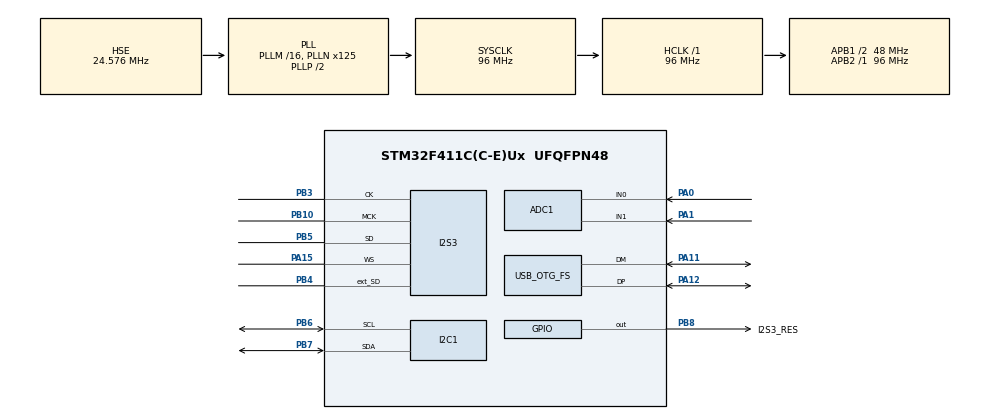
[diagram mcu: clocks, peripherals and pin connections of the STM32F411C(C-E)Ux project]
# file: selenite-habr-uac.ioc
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ADC1.Channel-0\#ChannelRegularConversion=ADC_CHANNEL_0
ADC1.Channel-1\#ChannelRegularConversion=ADC_CHANNEL_1
ADC1.ContinuousConvMode=DISABLE
ADC1.DMAContinuousRequests=ENABLE
ADC1.DataAlign=ADC_DATAALIGN_RIGHT
ADC1.ExternalTrigConv=ADC_EXTERNALTRIGCONV_T2_TRGO
ADC1.ExternalTrigConvEdge=ADC_EXTERNALTRIGCONVEDGE_RISINGFALLING
ADC1.NbrOfConversion=2
ADC1.NbrOfConversionFlag=1
ADC1.Rank-0\#ChannelRegularConversion=1
ADC1.Rank-1\#ChannelRegularConversion=2
ADC1.SamplingTime-0\#ChannelRegularConversion=ADC_SAMPLETIME_15CYCLES
ADC1.SamplingTime-1\#ChannelRegularConversion=ADC_SAMPLETIME_15CYCLES
ADC1.master=1
Dma.ADC1.2.Direction=DMA_PERIPH_TO_MEMORY
Dma.ADC1.2.FIFOMode=DMA_FIFOMODE_ENABLE
Dma.ADC1.2.FIFOThreshold=DMA_FIFO_THRESHOLD_FULL
Dma.ADC1.2.Instance=DMA2_Stream0
Dma.ADC1.2.MemBurst=DMA_MBURST_INC8
Dma.ADC1.2.MemDataAlignment=DMA_MDATAALIGN_HALFWORD
Dma.ADC1.2.MemInc=DMA_MINC_ENABLE
Dma.ADC1.2.Mode=DMA_CIRCULAR
Dma.ADC1.2.PeriphBurst=DMA_PBURST_SINGLE
Dma.ADC1.2.PeriphDataAlignment=DMA_PDATAALIGN_HALFWORD
Dma.ADC1.2.PeriphInc=DMA_PINC_DISABLE
Dma.ADC1.2.Priority=DMA_PRIORITY_LOW
Dma.I2S3_EXT_RX.0.Direction=DMA_PERIPH_TO_MEMORY
Dma.I2S3_EXT_RX.0.FIFOMode=DMA_FIFOMODE_ENABLE
Dma.I2S3_EXT_RX.0.FIFOThreshold=DMA_FIFO_THRESHOLD_FULL
Dma.I2S3_EXT_RX.0.Instance=DMA1_Stream0
Dma.I2S3_EXT_RX.0.MemBurst=DMA_MBURST_INC8
Dma.I2S3_EXT_RX.0.MemDataAlignment=DMA_MDATAALIGN_HALFWORD
Dma.I2S3_EXT_RX.0.MemInc=DMA_MINC_ENABLE
Dma.I2S3_EXT_RX.0.Mode=DMA_CIRCULAR
Dma.I2S3_EXT_RX.0.PeriphBurst=DMA_PBURST_SINGLE
Dma.I2S3_EXT_RX.0.PeriphDataAlignment=DMA_PDATAALIGN_HALFWORD
Dma.I2S3_EXT_RX.0.PeriphInc=DMA_PINC_DISABLE
Dma.I2S3_EXT_RX.0.Priority=DMA_PRIORITY_LOW
Dma.Request0=I2S3_EXT_RX
Dma.Request1=SPI3_TX
Dma.Request2=ADC1
Dma.SPI3_TX.1.Direction=DMA_MEMORY_TO_PERIPH
Dma.SPI3_TX.1.FIFOMode=DMA_FIFOMODE_ENABLE
Dma.SPI3_TX.1.FIFOThreshold=DMA_FIFO_THRESHOLD_FULL
Dma.SPI3_TX.1.Instance=DMA1_Stream5
Dma.SPI3_TX.1.MemBurst=DMA_MBURST_INC8
Dma.SPI3_TX.1.MemDataAlignment=DMA_MDATAALIGN_HALFWORD
Dma.SPI3_TX.1.MemInc=DMA_MINC_ENABLE
Dma.SPI3_TX.1.Mode=DMA_CIRCULAR
Dma.SPI3_TX.1.PeriphBurst=DMA_PBURST_SINGLE
Dma.SPI3_TX.1.PeriphDataAlignment=DMA_PDATAALIGN_HALFWORD
Dma.SPI3_TX.1.PeriphInc=DMA_PINC_DISABLE
Dma.SPI3_TX.1.Priority=DMA_PRIORITY_LOW
I2S3.AudioFreq=I2S_AUDIOFREQ_48K
I2S3.ClockSource=I2S_CLOCK_PLL
I2S3.ErrorAudioFreq=0.0 %
I2S3.FullDuplexMode=I2S_FULLDUPLEXMODE_ENABLE
I2S3.Instance=SPI$Index
I2S3.RealAudioFreq=48.0 KHz
I2S3.VirtualMode=I2S_MODE_MASTER
Mcu.Family=STM32F4
Mcu.Name=STM32F411C(C-E)Ux
Mcu.Package=UFQFPN48
NVIC.DMA1_Stream0_IRQn=true\:0\:0\:false\:false\:true\:false\:true\:true
NVIC.DMA1_Stream5_IRQn=true\:0\:0\:false\:false\:true\:false\:true\:true
NVIC.DMA2_Stream0_IRQn=true\:0\:0\:false\:false\:true\:false\:true\:true
NVIC.OTG_FS_IRQn=true\:0\:0\:false\:false\:true\:false\:true\:true
NVIC.PriorityGroup=NVIC_PRIORITYGROUP_4
PA0-WKUP.Signal=ADCx_IN0
PA1.Signal=ADCx_IN1
PA11.Mode=Device_Only
PA11.Signal=USB_OTG_FS_DM
PA12.Mode=Device_Only
PA12.Signal=USB_OTG_FS_DP
PA13.Mode=Serial_Wire
PA13.Signal=SYS_JTMS-SWDIO
PA14.Mode=Serial_Wire
PA14.Signal=SYS_JTCK-SWCLK
PA15.Mode=Full_Duplex_Master
PA15.Signal=I2S3_WS
PB10.Mode=Master_Clock_Activated
PB10.Signal=I2S3_MCK
PB3.Mode=Full_Duplex_Master
PB3.Signal=I2S3_CK
PB4.Mode=Full_Duplex_Master
PB4.Signal=I2S3_ext_SD
PB5.Mode=Full_Duplex_Master
PB5.Signal=I2S3_SD
PB6.GPIO_Pu=GPIO_PULLUP
PB6.Mode=I2C
PB6.Signal=I2C1_SCL
PB7.GPIO_Pu=GPIO_PULLUP
PB7.Mode=I2C
PB7.Signal=I2C1_SDA
PB8.GPIO_Label=I2S3_RES
PB8.GPIO_ModeDefaultOutputPP=GPIO_MODE_OUTPUT_PP
PB8.GPIO_PuPd=GPIO_PULLUP
PB8.PinState=GPIO_PIN_SET
PB8.Signal=GPIO_Output
PH0\ -\ OSC_IN.Mode=HSE-External-Clock-Source
PH0\ -\ OSC_IN.Signal=RCC_OSC_IN
PH1\ -\ OSC_OUT.Mode=HSE-External-Clock-Source
PH1\ -\ OSC_OUT.Signal=RCC_OSC_OUT
ProjectManager.HeapSize=0x200
ProjectManager.StackSize=0x400
ProjectManager.TargetToolchain=STM32CubeIDE
RCC.48MHZClocksFreq_Value=48000000
RCC.AHBFreq_Value=96000000
RCC.APB1CLKDivider=RCC_HCLK_DIV2
RCC.APB1Freq_Value=48000000
RCC.APB1TimFreq_Value=96000000
RCC.APB2Freq_Value=96000000
RCC.APB2TimFreq_Value=96000000
RCC.CortexFreq_Value=96000000
RCC.EXTERNAL_CLOCK_VALUE=98304000
RCC.HCLKFreq_Value=96000000
RCC.HSE_VALUE=24576000
RCC.HSI_VALUE=16000000
RCC.LSE_VALUE=32768
RCC.PLLI2SN=128
RCC.PLLI2SR=4
RCC.PLLN=125
RCC.PWREXT_OverDrive=PWREXT_OverDrive_DESACTIVATED
RCC.RCC_MCO1Source=RCC_MCO1SOURCE_HSE
RCC.RCC_RTC_Clock_Source=RCC_RTCCLKSOURCE_LSI
RCC.RCC_RTC_Clock_SourceVirtual=RCC_RTCCLKSOURCE_LSE
RCC.SYSCLKFreq_VALUE=96000000
RCC.SYSCLKSource=RCC_SYSCLKSOURCE_PLLCLK
RCC.VCOOutputFreq_Value=192000000
SH.ADCx_IN0.0=ADC1_IN0,IN0
SH.ADCx_IN1.0=ADC1_IN1,IN1
TIM2.TIM_MasterOutputTrigger=TIM_TRGO_UPDATE
USB_DEVICE.APP_RX_DATA_SIZE=64
USB_DEVICE.APP_TX_DATA_SIZE=64
USB_DEVICE.CLASS_NAME_FS=CDC
USB_DEVICE.CONFIGURATION_STRING_CDC_FS=Selenite TRX Config
USB_DEVICE.INTERFACE_STRING_CDC_FS=Selenite TRX Interface
USB_DEVICE.PID_CDC_FS=22347
USB_DEVICE.PRODUCT_STRING_CDC_FS=Selenite TRX
USB_DEVICE.USBD_MAX_NUM_INTERFACES=5
USB_DEVICE.VirtualMode=Cdc
USB_DEVICE.VirtualModeFS=Cdc_FS
USB_OTG_FS.VirtualMode=Device_Only
VP_TIM2_VS_ClockSourceINT.Mode=Internal
VP_USB_DEVICE_VS_USB_DEVICE_CDC_FS.Mode=CDC_FS
board=custom

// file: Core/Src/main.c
/* USER CODE BEGIN Header */
/**
  ******************************************************************************
  * @file           : main.c
  * @brief          : Main program body
  ******************************************************************************
  * @attention
  *
  * <h2><center>&copy; Copyright (c) 2021 STMicroelectronics.
  * All rights reserved.</center></h2>
  *
  * This software component is licensed by ST under BSD 3-Clause license,
  * the "License"; You may not use this file except in compliance with the
  * License. You may obtain a copy of the License at:
  *                        opensource.org/licenses/BSD-3-Clause
  *
  ******************************************************************************
  */
/* USER CODE END Header */
#include "main.h"
#include "usb_device.h"

/* USER CODE BEGIN Includes */

#include "dsp_if.h"

/* USER CODE END Includes */

ADC_HandleTypeDef hadc1;
DMA_HandleTypeDef hdma_adc1;

I2C_HandleTypeDef hi2c1;

I2S_HandleTypeDef hi2s3;
DMA_HandleTypeDef hdma_i2s3_ext_rx;
DMA_HandleTypeDef hdma_spi3_tx;

TIM_HandleTypeDef htim2;

void SystemClock_Config(void);
static void MX_GPIO_Init(void);
static void MX_I2C1_Init(void);
static void MX_DMA_Init(void);
static void MX_I2S3_Init(void);
static void MX_ADC1_Init(void);
static void MX_TIM2_Init(void);

int main(void)
{

  /* MCU Configuration--------------------------------------------------------*/

  /* Reset of all peripherals, Initializes the Flash interface and the Systick. */
  HAL_Init();

  /* USER CODE BEGIN Init */

#if (SI5351)
  __HAL_RCC_GPIOB_CLK_ENABLE ();
  MX_I2C1_Init ();

  DSP_Set_HSE ();   //Set HSE = 24.576 MHz from VFO
#endif /* SI5351 */

  /* USER CODE END Init */

  /* Configure the system clock */
  SystemClock_Config();

  /* Initialize all configured peripherals */
  MX_GPIO_Init();
  MX_USB_DEVICE_Init();
  MX_I2C1_Init();
  MX_DMA_Init();
  MX_I2S3_Init();
  MX_ADC1_Init();
  MX_TIM2_Init();
  /* USER CODE BEGIN 2 */

  DSP_Init ();

  /* USER CODE END 2 */

  /* Infinite loop */
  while (1)
  {

  }
}

void SystemClock_Config(void)
{
  RCC_OscInitTypeDef RCC_OscInitStruct = {0};
  RCC_ClkInitTypeDef RCC_ClkInitStruct = {0};

  /** Configure the main internal regulator output voltage
  */
  __HAL_RCC_PWR_CLK_ENABLE();
  __HAL_PWR_VOLTAGESCALING_CONFIG(PWR_REGULATOR_VOLTAGE_SCALE1);

  /** Initializes the RCC Oscillators according to the specified parameters
  * in the RCC_OscInitTypeDef structure.
  */
  RCC_OscInitStruct.OscillatorType = RCC_OSCILLATORTYPE_HSE;
  RCC_OscInitStruct.HSEState = RCC_HSE_BYPASS;
  RCC_OscInitStruct.PLL.PLLState = RCC_PLL_ON;
  RCC_OscInitStruct.PLL.PLLSource = RCC_PLLSOURCE_HSE;
  RCC_OscInitStruct.PLL.PLLM = 16;
  RCC_OscInitStruct.PLL.PLLN = 125;
  RCC_OscInitStruct.PLL.PLLP = RCC_PLLP_DIV2;
  RCC_OscInitStruct.PLL.PLLQ = 4;
  if (HAL_RCC_OscConfig(&RCC_OscInitStruct) != HAL_OK)
  {
    Error_Handler();
  }

  /** Initializes the CPU, AHB and APB buses clocks
  */
  RCC_ClkInitStruct.ClockType = RCC_CLOCKTYPE_HCLK|RCC_CLOCKTYPE_SYSCLK
                              |RCC_CLOCKTYPE_PCLK1|RCC_CLOCKTYPE_PCLK2;
  RCC_ClkInitStruct.SYSCLKSource = RCC_SYSCLKSOURCE_PLLCLK;
  RCC_ClkInitStruct.AHBCLKDivider = RCC_SYSCLK_DIV1;
  RCC_ClkInitStruct.APB1CLKDivider = RCC_HCLK_DIV2;
  RCC_ClkInitStruct.APB2CLKDivider = RCC_HCLK_DIV1;

  if (HAL_RCC_ClockConfig(&RCC_ClkInitStruct, FLASH_LATENCY_3) != HAL_OK)
  {
    Error_Handler();
  }
}

static void MX_ADC1_Init(void)
{

  ADC_ChannelConfTypeDef sConfig = {0};

  /** Configure the global features of the ADC (Clock, Resolution, Data Alignment and number of conversion)
  */
  hadc1.Instance = ADC1;
  hadc1.Init.ClockPrescaler = ADC_CLOCK_SYNC_PCLK_DIV4;
  hadc1.Init.Resolution = ADC_RESOLUTION_12B;
  hadc1.Init.ScanConvMode = ENABLE;
  hadc1.Init.ContinuousConvMode = DISABLE;
  hadc1.Init.DiscontinuousConvMode = DISABLE;
  hadc1.Init.ExternalTrigConvEdge = ADC_EXTERNALTRIGCONVEDGE_RISINGFALLING;
  hadc1.Init.ExternalTrigConv = ADC_EXTERNALTRIGCONV_T2_TRGO;
  hadc1.Init.DataAlign = ADC_DATAALIGN_RIGHT;
  hadc1.Init.NbrOfConversion = 2;
  hadc1.Init.DMAContinuousRequests = ENABLE;
  hadc1.Init.EOCSelection = ADC_EOC_SINGLE_CONV;
  if (HAL_ADC_Init(&hadc1) != HAL_OK)
  {
    Error_Handler();
  }

  /** Configure for the selected ADC regular channel its corresponding rank in the sequencer and its sample time.
  */
  sConfig.Channel = ADC_CHANNEL_0;
  sConfig.Rank = 1;
  sConfig.SamplingTime = ADC_SAMPLETIME_15CYCLES;
  if (HAL_ADC_ConfigChannel(&hadc1, &sConfig) != HAL_OK)
  {
    Error_Handler();
  }

  /** Configure for the selected ADC regular channel its corresponding rank in the sequencer and its sample time.
  */
  sConfig.Channel = ADC_CHANNEL_1;
  sConfig.Rank = 2;
  if (HAL_ADC_ConfigChannel(&hadc1, &sConfig) != HAL_OK)
  {
    Error_Handler();
  }

}

static void MX_I2C1_Init(void)
{

  hi2c1.Instance = I2C1;
  hi2c1.Init.ClockSpeed = 100000;
  hi2c1.Init.DutyCycle = I2C_DUTYCYCLE_2;
  hi2c1.Init.OwnAddress1 = 0;
  hi2c1.Init.AddressingMode = I2C_ADDRESSINGMODE_7BIT;
  hi2c1.Init.DualAddressMode = I2C_DUALADDRESS_DISABLE;
  hi2c1.Init.OwnAddress2 = 0;
  hi2c1.Init.GeneralCallMode = I2C_GENERALCALL_DISABLE;
  hi2c1.Init.NoStretchMode = I2C_NOSTRETCH_DISABLE;
  if (HAL_I2C_Init(&hi2c1) != HAL_OK)
  {
    Error_Handler();
  }

}

static void MX_I2S3_Init(void)
{

  hi2s3.Instance = SPI3;
  hi2s3.Init.Mode = I2S_MODE_MASTER_TX;
  hi2s3.Init.Standard = I2S_STANDARD_PHILIPS;
  hi2s3.Init.DataFormat = I2S_DATAFORMAT_16B;
  hi2s3.Init.MCLKOutput = I2S_MCLKOUTPUT_ENABLE;
  hi2s3.Init.AudioFreq = I2S_AUDIOFREQ_48K;
  hi2s3.Init.CPOL = I2S_CPOL_LOW;
  hi2s3.Init.ClockSource = I2S_CLOCK_PLL;
  hi2s3.Init.FullDuplexMode = I2S_FULLDUPLEXMODE_ENABLE;
  if (HAL_I2S_Init(&hi2s3) != HAL_OK)
  {
    Error_Handler();
  }

}

static void MX_TIM2_Init(void)
{

  TIM_ClockConfigTypeDef sClockSourceConfig = {0};
  TIM_MasterConfigTypeDef sMasterConfig = {0};

  htim2.Instance = TIM2;
  htim2.Init.Prescaler = 0;
  htim2.Init.CounterMode = TIM_COUNTERMODE_UP;
  htim2.Init.Period = 4294967295;
  htim2.Init.ClockDivision = TIM_CLOCKDIVISION_DIV1;
  htim2.Init.AutoReloadPreload = TIM_AUTORELOAD_PRELOAD_DISABLE;
  if (HAL_TIM_Base_Init(&htim2) != HAL_OK)
  {
    Error_Handler();
  }
  sClockSourceConfig.ClockSource = TIM_CLOCKSOURCE_INTERNAL;
  if (HAL_TIM_ConfigClockSource(&htim2, &sClockSourceConfig) != HAL_OK)
  {
    Error_Handler();
  }
  sMasterConfig.MasterOutputTrigger = TIM_TRGO_UPDATE;
  sMasterConfig.MasterSlaveMode = TIM_MASTERSLAVEMODE_DISABLE;
  if (HAL_TIMEx_MasterConfigSynchronization(&htim2, &sMasterConfig) != HAL_OK)
  {
    Error_Handler();
  }

}

static void MX_DMA_Init(void)
{

  /* DMA controller clock enable */
  __HAL_RCC_DMA1_CLK_ENABLE();
  __HAL_RCC_DMA2_CLK_ENABLE();

  /* DMA interrupt init */
  /* DMA1_Stream0_IRQn interrupt configuration */
  HAL_NVIC_SetPriority(DMA1_Stream0_IRQn, 0, 0);
  HAL_NVIC_EnableIRQ(DMA1_Stream0_IRQn);
  /* DMA1_Stream5_IRQn interrupt configuration */
  HAL_NVIC_SetPriority(DMA1_Stream5_IRQn, 0, 0);
  HAL_NVIC_EnableIRQ(DMA1_Stream5_IRQn);
  /* DMA2_Stream0_IRQn interrupt configuration */
  HAL_NVIC_SetPriority(DMA2_Stream0_IRQn, 0, 0);
  HAL_NVIC_EnableIRQ(DMA2_Stream0_IRQn);

}

static void MX_GPIO_Init(void)
{
  GPIO_InitTypeDef GPIO_InitStruct = {0};

  /* GPIO Ports Clock Enable */
  __HAL_RCC_GPIOH_CLK_ENABLE();
  __HAL_RCC_GPIOA_CLK_ENABLE();
  __HAL_RCC_GPIOB_CLK_ENABLE();

  /*Configure GPIO pin Output Level */
  HAL_GPIO_WritePin(I2S3_RES_GPIO_Port, I2S3_RES_Pin, GPIO_PIN_SET);

  /*Configure GPIO pin : I2S3_RES_Pin */
  GPIO_InitStruct.Pin = I2S3_RES_Pin;
  GPIO_InitStruct.Mode = GPIO_MODE_OUTPUT_PP;
  GPIO_InitStruct.Pull = GPIO_PULLUP;
  GPIO_InitStruct.Speed = GPIO_SPEED_FREQ_LOW;
  HAL_GPIO_Init(I2S3_RES_GPIO_Port, &GPIO_InitStruct);

}

void Error_Handler(void)
{
}
